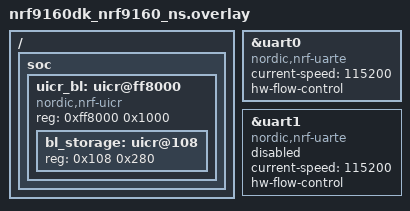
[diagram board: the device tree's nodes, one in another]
/*
 * Copyright (c) 2026 Nordic Semiconductor ASA
 *
 * SPDX-License-Identifier: LicenseRef-Nordic-5-Clause
 */

#include <samples/cellular/nrf91_crypto_partitions.dtsi>

#include <samples/cellular/nrf91_sram_crypto_partitions.dtsi>

&uart0 {
	compatible = "nordic,nrf-uarte";
	current-speed = <115200>;
	status = "okay";
	hw-flow-control;
};

&uart1 {
	compatible = "nordic,nrf-uarte";
	current-speed = <115200>;
	/* Set to disabled in application, since TF-M will be using it. */
	status = "disabled";
	hw-flow-control;
};

/* Resolve bl_storage in the forwarded TF-M secure image. */
/ {
	soc {
		uicr_bl: uicr@ff8000 {
			compatible = "nordic,nrf-uicr";
			reg = <0xff8000 0x1000>;
			ranges = <0x0 0xff8000 0x1000>;
			status = "okay";
			#address-cells = <1>;
			#size-cells = <1>;

			bl_storage: uicr@108 {
				reg = <0x108 0x280>;
			};
		};
	};
};
